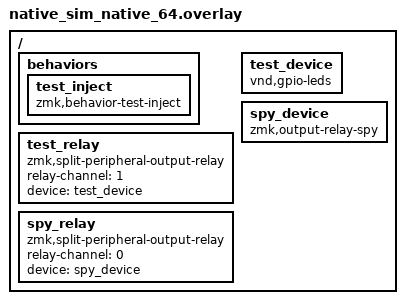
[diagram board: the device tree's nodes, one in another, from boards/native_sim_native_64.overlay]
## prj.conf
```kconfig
CONFIG_ZMK_TESTS=y
CONFIG_TEST=y
CONFIG_LOG=y
CONFIG_ZMK_LOG_LEVEL_DBG=y
CONFIG_BOOT_BANNER=n
CONFIG_LOG_MODE_IMMEDIATE=y

CONFIG_ZMK_BLE=y
CONFIG_BT=y
CONFIG_BT_PERIPHERAL=y
CONFIG_BT_CTLR=y
CONFIG_BT_LL_SW_SPLIT=y
CONFIG_ZMK_SPLIT=y
CONFIG_ZMK_SPLIT_ROLE_PERIPHERAL=y
CONFIG_ZMK_SPLT_PERIPHERAL_OUTPUT_RELAY=y
CONFIG_ZMK_TEST_INJECT=y
```

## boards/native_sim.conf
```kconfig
CONFIG_ZMK_TEST_INJECT=y
```

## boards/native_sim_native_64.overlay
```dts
/ {
    behaviors {
        test_inject: test_inject {
            compatible = "zmk,behavior-test-inject";
            #binding-cells = <0>;
        };
    };

	test_relay: test_relay {
		compatible = "zmk,split-peripheral-output-relay";
		relay-channel = <1>;
		device = <&test_device>;
	};

	test_device: test_device {
		compatible = "vnd,gpio-leds"; 
        status = "okay";
	};

    spy_relay: spy_relay {
        compatible = "zmk,split-peripheral-output-relay";
        relay-channel = <0>;
        device = <&spy_device>;
    };

    spy_device: spy_device {
        compatible = "zmk,output-relay-spy";
        status = "okay";
    };
};
```

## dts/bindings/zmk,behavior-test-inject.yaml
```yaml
description: Test Inject Behavior

compatible: "zmk,behavior-test-inject"
```

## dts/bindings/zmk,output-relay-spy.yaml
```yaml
description: Spy Relay Driver

compatible: "zmk,output-relay-spy"

include: base.yaml
```

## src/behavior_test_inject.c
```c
#define DT_DRV_COMPAT zmk_behavior_test_inject

#include <zephyr/device.h>
#include <zephyr/kernel.h>
#include <zephyr/init.h>
#include <drivers/behavior.h>
#include <zephyr/logging/log.h>
#include <zmk/behavior.h>
#include <zmk/split/output-relay/event.h>

LOG_MODULE_REGISTER(behavior_test_inject, CONFIG_ZMK_LOG_LEVEL);

// Declaration of the hidden injection function
extern int
zmk_split_peripheral_output_relay_test_inject_event(struct zmk_split_bt_output_relay_event *ev);

static int on_keymap_binding_pressed(struct zmk_behavior_binding *binding,
                                     struct zmk_behavior_binding_event event) {
#include <zephyr/sys/printk.h>

    printk("Test inject behavior pressed\n");

    struct zmk_split_bt_output_relay_event ev = {
        .relay_channel = 0, // Target channel 0
        .value = 123,       // Test value
    };

    // Inject the event as if it came from BLE
    zmk_split_peripheral_output_relay_test_inject_event(&ev);

    return ZMK_BEHAVIOR_OPAQUE;
}

static int on_keymap_binding_released(struct zmk_behavior_binding *binding,
                                      struct zmk_behavior_binding_event event) {
    return ZMK_BEHAVIOR_OPAQUE;
}

static const struct behavior_driver_api behavior_test_inject_driver_api = {
    .binding_pressed = on_keymap_binding_pressed,
    .binding_released = on_keymap_binding_released,
};

static int behavior_test_inject_init(const struct device *dev) {
    printk("Inject behavior initialized\n");
    k_busy_wait(2000000);
    return 0;
}

static int sys_init_debug(void) {
    printk("SYS_INIT debug: behavior_test_inject.c is linked and running!\n");
    return 0;
}
SYS_INIT(sys_init_debug, APPLICATION, 90);

#define TEST_INJECT_INST(n)                                                                        \
    BEHAVIOR_DT_INST_DEFINE(n, behavior_test_inject_init, NULL, NULL, NULL, POST_KERNEL,           \
                            CONFIG_KERNEL_INIT_PRIORITY_DEFAULT,                                   \
                            &behavior_test_inject_driver_api);

DT_INST_FOREACH_STATUS_OKAY(TEST_INJECT_INST)
```

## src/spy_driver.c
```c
#define DT_DRV_COMPAT zmk_output_relay_spy

#include <zephyr/device.h>
#include <zephyr/logging/log.h>
#include <zephyr/sys/printk.h>
#include <zmk/output/output_generic.h>

LOG_MODULE_REGISTER(spy_driver, CONFIG_ZMK_LOG_LEVEL);

static int spy_set_value(const struct device *dev, uint8_t value) {
    printk("Spy driver set_value called: %d\n", value);
    return 0;
}

static const struct output_generic_api spy_api = {
    .set_value = spy_set_value,
};

static int spy_init(const struct device *dev) { return 0; }

#define SPY_INST(n)                                                                                \
    DEVICE_DT_INST_DEFINE(n, spy_init, NULL, NULL, NULL, POST_KERNEL,                              \
                          CONFIG_APPLICATION_INIT_PRIORITY, &spy_api);

DT_INST_FOREACH_STATUS_OKAY(SPY_INST)
```
